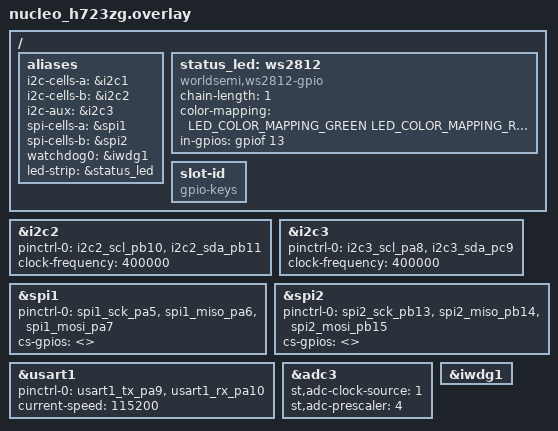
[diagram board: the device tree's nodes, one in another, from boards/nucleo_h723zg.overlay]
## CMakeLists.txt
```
cmake_minimum_required(VERSION 3.20.0)
find_package(Zephyr REQUIRED HINTS $ENV{ZEPHYR_BASE})
project(cellsim-card)

target_sources(app PRIVATE
    src/main.c
    src/card_id.c
    src/cell.c
    src/self_test.c
    src/watchdog.c
    src/health.c
    src/network.c
    src/led.c
)
```

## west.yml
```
manifest:
  remotes:
    - name: zephyrproject-rtos
      url-base: https://github.com/zephyrproject-rtos

  projects:
    - name: zephyr
      remote: zephyrproject-rtos
      revision: v4.0.0
      import:
        name-allowlist:
          - cmsis
          - hal_stm32
          - mbedtls
          - mcuboot
          - net-tools

  self:
    path: card
```

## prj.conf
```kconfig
# CellSim Card Firmware - Zephyr Configuration
# Target: STM32H723 + LAN8742A (Zephyr 4.0.0)

# --- Core ---
CONFIG_MAIN_STACK_SIZE=4096
CONFIG_HEAP_MEM_POOL_SIZE=16384
CONFIG_SYSTEM_WORKQUEUE_STACK_SIZE=2048

# --- Networking ---
CONFIG_NETWORKING=y
CONFIG_NET_IPV4=y
CONFIG_NET_TCP=y
CONFIG_NET_UDP=y
CONFIG_NET_SOCKETS=y

# Network buffers (required for TCP/UDP)
CONFIG_NET_PKT_RX_COUNT=16
CONFIG_NET_PKT_TX_COUNT=16
CONFIG_NET_BUF_RX_COUNT=32
CONFIG_NET_BUF_TX_COUNT=32
CONFIG_NET_MAX_CONTEXTS=8

# DHCP client (fallback to static if no DHCP)
CONFIG_NET_DHCPV4=y

# DNS / mDNS for card discovery
CONFIG_DNS_RESOLVER=y
CONFIG_MDNS_RESPONDER=y
CONFIG_DNS_SD=y
CONFIG_MDNS_RESOLVER=y
CONFIG_NET_HOSTNAME_ENABLE=y
CONFIG_NET_HOSTNAME_MAX_LEN=32
CONFIG_ZVFS_POLL_MAX=8

# --- Ethernet ---
CONFIG_NET_L2_ETHERNET=y
CONFIG_ETH_STM32_HAL=y

# --- I2C ---
CONFIG_I2C=y

# --- SPI (cell ADCs: ADS131M04 via ISO7741 isolators) ---
CONFIG_SPI=y

# --- GPIO ---
CONFIG_GPIO=y

# --- ADC (internal, for input voltage + temperature) ---
CONFIG_ADC=y

# --- Sensor (needed for STM32 internal temp sensor driver) ---
CONFIG_SENSOR=y

# --- MCUboot (OTA firmware update) ---
# Disabled for initial build — requires MCUboot partition table + signing key.
# Re-enable once bootloader integration is done.
# CONFIG_BOOTLOADER_MCUBOOT=y

# --- MCUmgr (SMP over UDP for firmware push from CM5) ---
# Disabled until MCUboot is enabled.
# CONFIG_MCUMGR=y
# CONFIG_MCUMGR_TRANSPORT_UDP=y
# CONFIG_MCUMGR_GRP_IMG=y
# CONFIG_MCUMGR_GRP_OS=y

# --- UART (backplane slot mux for remote flash/debug) ---
CONFIG_SERIAL=y

# --- Watchdog (hardware IWDG for firmware hang recovery) ---
CONFIG_WATCHDOG=y

# --- Internal temperature sensor ---
# Disabled: requires die_temp DT node which nucleo_h723zg base DTS doesn't define.
# Re-enable once custom board DTS is created with proper die_temp node.
# CONFIG_STM32_TEMP=y

# --- Shell (debug console over UART) ---
CONFIG_SHELL=y
CONFIG_SHELL_BACKEND_SERIAL=y

# --- Logging ---
CONFIG_LOG=y
CONFIG_LOG_DEFAULT_LEVEL=3

# --- Status LED (SK6805-EC20, WS2812-compatible via GPIO bit-bang) ---
CONFIG_LED_STRIP=y
CONFIG_WS2812_STRIP=y
CONFIG_WS2812_STRIP_GPIO=y

# --- Reboot support (for CMD_REBOOT) ---
CONFIG_REBOOT=y

# --- Float support (needed for health monitoring printfs) ---
CONFIG_FPU=y
CONFIG_CBPRINTF_FP_SUPPORT=y
```

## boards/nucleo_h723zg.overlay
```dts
/*
 * CellSim Card - Zephyr Device Tree Overlay
 *
 * Based on nucleo_h723zg, customized for the CellSim card PCB.
 *
 * I2C Bus Architecture (control path — DACs, GPIO, temp):
 *   i2c1 -> TCA9548A #1 -> cells 0-3 (each behind ISO1640)
 *   i2c2 -> TCA9548A #2 -> cells 4-7 (each behind ISO1640)
 *   i2c3 -> 24AA025E48 EEPROM (card identity) + board temp sensor
 *
 * SPI Bus Architecture (measurement path — ADC):
 *   spi1 -> ISO7741 ×4 -> cells 0-3 ADS131M04 (MISO via CD74HC4052)
 *   spi2 -> ISO7741 ×4 -> cells 4-7 ADS131M04 (MISO via CD74HC4052)
 *
 * UART:
 *   usart1 -> backplane slot mux -> CM5 (remote debug/flash)
 *   usart3 -> ST-LINK virtual COM (debug console, default on base board)
 *
 * ADC:
 *   adc3 -> internal temp (ch18), Vrefint (ch19), input voltage divider
 *
 * Ethernet:
 *   RMII -> LAN8742A -> backplane (configured in base board DTS)
 *
 * TODO: Finalize pin assignments once PCB layout is done.
 *       These are reasonable defaults for the nucleo_h723zg.
 */

#include <st/h7/stm32h723zgtx-pinctrl.dtsi>
#include <dt-bindings/led/led.h>

/ {
    aliases {
        /* I2C buses for cell blocks (control path) */
        i2c-cells-a = &i2c1;
        i2c-cells-b = &i2c2;
        i2c-aux = &i2c3;

        /* SPI buses for cell ADCs (measurement path) */
        spi-cells-a = &spi1;
        spi-cells-b = &spi2;

        /* Hardware watchdog */
        watchdog0 = &iwdg1;

        /* Status LED (SK6805-EC20, WS2812-compatible) */
        led-strip = &status_led;
    };

    /* SK6805-EC20 addressable RGB status LED on PF13 */
    status_led: ws2812 {
        compatible = "worldsemi,ws2812-gpio";
        chain-length = <1>;
        color-mapping = <LED_COLOR_MAPPING_GREEN
                         LED_COLOR_MAPPING_RED
                         LED_COLOR_MAPPING_BLUE>;
        in-gpios = <&gpiof 13 0>;
    };

    /* Slot ID GPIO inputs (active-low, coded by backplane resistors) */
    slot-id {
        compatible = "gpio-keys";
        /* TODO: assign actual GPIO pins once schematic is finalized
         * 4 bits for 16 slots (reduced from 5 bits / 20 slots)
         *
         * Example (placeholder pins):
         * slot-id-0 { gpios = <&gpiod 0 (GPIO_PULL_UP | GPIO_ACTIVE_LOW)>; };
         * slot-id-1 { gpios = <&gpiod 1 (GPIO_PULL_UP | GPIO_ACTIVE_LOW)>; };
         * slot-id-2 { gpios = <&gpiod 2 (GPIO_PULL_UP | GPIO_ACTIVE_LOW)>; };
         * slot-id-3 { gpios = <&gpiod 3 (GPIO_PULL_UP | GPIO_ACTIVE_LOW)>; };
         */
    };

    /*
     * SPI ADC chip-select and MISO mux GPIO pins.
     * Each SPI bus has:
     *   4× CS lines (one per cell's ADS131M04, directly to ISO7741)
     *   2× MISO mux select (CD74HC4052 address bits A0/A1)
     *
     * TODO: assign actual GPIO pins once schematic is finalized.
     *
     * spi1-adc-gpios {
     *     compatible = "gpio-leds";
     *     spi1_cs0 { gpios = <&gpioe 0 GPIO_ACTIVE_LOW>; };
     *     spi1_cs1 { gpios = <&gpioe 1 GPIO_ACTIVE_LOW>; };
     *     spi1_cs2 { gpios = <&gpioe 2 GPIO_ACTIVE_LOW>; };
     *     spi1_cs3 { gpios = <&gpioe 3 GPIO_ACTIVE_LOW>; };
     *     spi1_mux_a0 { gpios = <&gpioe 4 GPIO_ACTIVE_HIGH>; };
     *     spi1_mux_a1 { gpios = <&gpioe 5 GPIO_ACTIVE_HIGH>; };
     * };
     *
     * spi2-adc-gpios {
     *     compatible = "gpio-leds";
     *     spi2_cs0 { gpios = <&gpioe 6 GPIO_ACTIVE_LOW>; };
     *     spi2_cs1 { gpios = <&gpioe 7 GPIO_ACTIVE_LOW>; };
     *     spi2_cs2 { gpios = <&gpioe 8 GPIO_ACTIVE_LOW>; };
     *     spi2_cs3 { gpios = <&gpioe 9 GPIO_ACTIVE_LOW>; };
     *     spi2_mux_a0 { gpios = <&gpioe 10 GPIO_ACTIVE_HIGH>; };
     *     spi2_mux_a1 { gpios = <&gpioe 11 GPIO_ACTIVE_HIGH>; };
     * };
     */
};

/* I2C1: Cells 0-3 (via TCA9548A #1) — pinctrl from base board (PB8/PB9) */
/* Already configured in base board DTS, just override clock if needed */

/* I2C2: Cells 4-7 (via TCA9548A #2) — PB10 (SCL), PB11 (SDA) */
&i2c2 {
    pinctrl-0 = <&i2c2_scl_pb10 &i2c2_sda_pb11>;
    pinctrl-names = "default";
    status = "okay";
    clock-frequency = <400000>;
};

/* I2C3: Card identity EEPROM (24AA025E48) + board temp sensor — PA8 (SCL), PC9 (SDA) */
&i2c3 {
    pinctrl-0 = <&i2c3_scl_pa8 &i2c3_sda_pc9>;
    pinctrl-names = "default";
    status = "okay";
    clock-frequency = <400000>;
};

/* SPI1: Cells 0-3 ADC (ADS131M04 via ISO7741) — PA5 (SCK), PA7 (MOSI), PA6 (MISO) */
&spi1 {
    pinctrl-0 = <&spi1_sck_pa5 &spi1_miso_pa6 &spi1_mosi_pa7>;
    pinctrl-names = "default";
    status = "okay";
    /* CS managed by software GPIO (per-cell through ISO7741) */
    cs-gpios = <>;
};

/* SPI2: Cells 4-7 ADC (ADS131M04 via ISO7741) — PB13 (SCK), PB15 (MOSI), PB14 (MISO) */
&spi2 {
    pinctrl-0 = <&spi2_sck_pb13 &spi2_miso_pb14 &spi2_mosi_pb15>;
    pinctrl-names = "default";
    status = "okay";
    cs-gpios = <>;
};

/* USART1: Backplane slot mux (remote debug/flash from CM5) — PA9 (TX), PA10 (RX) */
&usart1 {
    pinctrl-0 = <&usart1_tx_pa9 &usart1_rx_pa10>;
    pinctrl-names = "default";
    status = "okay";
    current-speed = <115200>;
};

/* ADC3: Internal sensors + input voltage divider */
&adc3 {
    status = "okay";
    st,adc-clock-source = <1>;  /* SYNC clock (AHB bus clock / prescaler) */
    st,adc-prescaler = <4>;     /* AHB clock prescaler */
    /* Internal channels (temp sensor ch18, Vrefint ch19) are always available.
     * External channel for input voltage divider: TODO assign pin/channel.
     */
};

/* Independent Watchdog (IWDG) */
&iwdg1 {
    status = "okay";
};

/* Ethernet: RMII to LAN8742A PHY — pinctrl from base board DTS */
/* &mac and &mdio already configured in base board DTS */
```

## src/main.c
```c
/*
 * CellSim Card Firmware
 * =====================
 * Zephyr RTOS application for the CellSim v2 cell card.
 *
 * Architecture:
 *   - 100 Hz control loop: reads ADCs, updates DACs, runs calibration
 *   - UDP streaming: sends measurement packets to CM5 at 100 Hz
 *   - TCP command server: receives commands from CM5
 *   - mDNS: advertises as cellsim-card-{slot_id}.local
 *   - MCUmgr/SMP: OTA firmware update over UDP
 *   - Self-test: BIST on all 8 cells at boot + on demand
 *   - Watchdog: hardware IWDG + CM5 heartbeat monitor
 *   - Health: internal temp, Vrefint, input voltage in every packet
 *
 * I2C topology (per card):
 *   I2C1 -> TCA9548A -> [ISO1640 -> cell devices] x 4  (cells 0-3)
 *   I2C2 -> TCA9548A -> [ISO1640 -> cell devices] x 4  (cells 4-7)
 *
 * Per-cell devices (on isolated side):
 *   - MCP4725 DAC ×2 (buck + LDO setpoints, via I2C)
 *   - ADS131M04 ADC (4ch simultaneous, via SPI + ISO7741 isolator)
 *   - TCA6408 GPIO expander (relay, enable, load switch, 2/4-wire, via I2C)
 *   - TMP117 temperature sensor (via I2C)
 *
 * Backplane signals:
 *   - USART1 (PA9 TX, PA10 RX): remote debug/flash via CM5 slot mux
 *   - BOOT0: ROM bootloader entry (pulled low on card, driven by CM5 mux)
 *   - NRST: reset (pulled high on card, driven by CM5 mux)
 *   - Slot ID: 4 GPIO inputs (active-low, coded by backplane resistors)
 *   - Input voltage: ADC3 via 100k/10k divider from 24V bus
 */

#include <zephyr/kernel.h>
#include <zephyr/drivers/gpio.h>
#include <zephyr/logging/log.h>

#include "card_id.h"
#include "cell.h"
#include "led.h"
#include "self_test.h"
#include "watchdog.h"
#include "health.h"
#include "network.h"

LOG_MODULE_REGISTER(cellsim, LOG_LEVEL_INF);

/* Firmware version (embedded in mDNS TXT record and self-test response) */
#define FW_VERSION_MAJOR 2
#define FW_VERSION_MINOR 0
#define FW_VERSION_PATCH 0

/**
 * Read slot ID from 4 GPIO pins (active-low, coded by backplane resistors).
 * Returns 0-15 for valid slots.
 */
static uint8_t read_slot_id(void)
{
    /* TODO: read 4 GPIO pins and decode slot ID
     * Slot ID pins are active-low: 0 = pull-down on backplane, 1 = pull-up
     * Binary encoding: slot_id = ~(GPIO3:GPIO0) & 0x0F
     */
    return 0; /* Placeholder: slot 0 */
}

int main(void)
{
    LOG_INF("CellSim card firmware v%d.%d.%d starting...",
            FW_VERSION_MAJOR, FW_VERSION_MINOR, FW_VERSION_PATCH);

    /* Read slot ID from backplane resistor coding */
    uint8_t slot_id = read_slot_id();
    LOG_INF("Slot ID: %d", slot_id);

    /* Read card identity EEPROM (24AA025E48 on I2C3) */
    int ret = card_id_init();
    if (ret != 0) {
        LOG_WRN("Card identity EEPROM read failed: %d (using fallback ID)", ret);
    }

    /* Initialize status LED and set booting color (blue) */
    ret = led_init();
    if (ret != 0) {
        LOG_WRN("Status LED init failed: %d (continuing without LED)", ret);
    } else {
        led_set_status_booting();
    }

    /* Initialize health monitoring (ADC3: internal temp, Vrefint, input voltage) */
    ret = health_init();
    if (ret != 0) {
        LOG_WRN("Health monitoring init failed: %d (continuing)", ret);
    }

    /* Initialize watchdog (hardware IWDG + CM5 heartbeat monitor) */
    ret = watchdog_init();
    if (ret != 0) {
        LOG_ERR("Watchdog init failed: %d", ret);
        /* Continue anyway — watchdog is important but not fatal */
    }

    /* Run self-test on all 8 cells */
    struct self_test_result st_result;
    ret = self_test_run(&st_result);
    if (ret != 0) {
        LOG_ERR("Self-test failed to run: %d", ret);
    } else if (!st_result.all_passed) {
        LOG_WRN("Self-test: some cells FAILED (MCU: %.1f°C, Vin: %.1fV)",
                (double)st_result.mcu_temp_celsius,
                (double)st_result.input_voltage);
        led_set_status_warning();
    } else {
        LOG_INF("Self-test: ALL PASSED (MCU: %.1f°C, Vin: %.1fV)",
                (double)st_result.mcu_temp_celsius,
                (double)st_result.input_voltage);
        led_set_status_ok();
    }

    /* Initialize cell control HAL (DACs, ADCs, GPIO expanders) */
    ret = cell_init();
    if (ret != 0) {
        LOG_ERR("Cell HAL init failed: %d", ret);
        /* Non-fatal: some cells may still work */
    }

    /* Initialize network services (mDNS, TCP, UDP) */
    ret = network_init(slot_id);
    if (ret != 0) {
        LOG_ERR("Network init failed: %d", ret);
        return ret;
    }

    /* Start TCP command server thread */
    ret = network_start_cmd_server();
    if (ret != 0) {
        LOG_ERR("Failed to start command server: %d", ret);
    }

    /* Start UDP measurement streaming + 100 Hz control loop */
    ret = network_start_meas_stream();
    if (ret != 0) {
        LOG_ERR("Failed to start measurement stream: %d", ret);
    }

    LOG_INF("CellSim card firmware initialized (slot %d)", slot_id);

    /* Main thread: nothing more to do, work happens in spawned threads.
     * Zephyr idle thread handles power management. */
    return 0;
}
```

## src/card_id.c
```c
/*
 * CellSim Card — Card Identity (24AA025E48 EEPROM) Implementation
 */

#include "card_id.h"

#include <zephyr/kernel.h>
#include <zephyr/device.h>
#include <zephyr/drivers/i2c.h>
#include <zephyr/logging/log.h>
#include <stdio.h>

LOG_MODULE_REGISTER(card_id, LOG_LEVEL_INF);

/* 24AA025E48 on I2C3 */
#define EEPROM_ADDR         0x50
#define EEPROM_EUI48_OFFSET 0xFA  /* EUI-48 starts at byte address 0xFA */

static uint8_t eui48[CARD_ID_EUI48_LEN];
static bool id_valid;

int card_id_init(void)
{
    const struct device *bus = DEVICE_DT_GET(DT_ALIAS(i2c_aux));
    if (!device_is_ready(bus)) {
        LOG_ERR("I2C3 (card identity bus) not ready");
        return -ENODEV;
    }

    /* Read 6 bytes starting at address 0xFA */
    uint8_t reg = EEPROM_EUI48_OFFSET;
    int ret = i2c_write_read(bus, EEPROM_ADDR, &reg, 1,
                             eui48, CARD_ID_EUI48_LEN);
    if (ret != 0) {
        LOG_ERR("24AA025E48 EEPROM read failed: %d", ret);
        id_valid = false;
        return ret;
    }

    /* Sanity: check it's not all-FF (blank EEPROM) or all-00 */
    bool all_ff = true, all_00 = true;
    for (int i = 0; i < CARD_ID_EUI48_LEN; i++) {
        if (eui48[i] != 0xFF) all_ff = false;
        if (eui48[i] != 0x00) all_00 = false;
    }

    if (all_ff || all_00) {
        LOG_WRN("EEPROM EUI-48 appears blank (all %s)",
                all_ff ? "0xFF" : "0x00");
        id_valid = false;
        return -ENODATA;
    }

    id_valid = true;

    char id_str[18];
    card_id_format_eui48(id_str, sizeof(id_str));
    LOG_INF("Card ID: %s", id_str);

    return 0;
}

bool card_id_get_eui48(uint8_t out[CARD_ID_EUI48_LEN])
{
    if (!id_valid || out == NULL) {
        return false;
    }
    memcpy(out, eui48, CARD_ID_EUI48_LEN);
    return true;
}

int card_id_format_eui48(char *buf, size_t buf_len)
{
    if (buf == NULL || buf_len < 18) {
        return 0;
    }
    return snprintf(buf, buf_len, "%02X:%02X:%02X:%02X:%02X:%02X",
                    eui48[0], eui48[1], eui48[2],
                    eui48[3], eui48[4], eui48[5]);
}
```

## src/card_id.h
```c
/*
 * CellSim Card — Card Identity (24AA025E48 EEPROM)
 *
 * Reads the factory-programmed EUI-48 from the Microchip 24AA025E48
 * EEPROM on I2C3. Used as:
 *   - Unique card identifier (survives MCU replacement)
 *   - Ethernet MAC address for LAN8742A
 *   - Calibration data binding key
 *
 * The EUI-48 is stored at EEPROM addresses 0xFA–0xFF (read-only).
 * The first 250 bytes (0x00–0xF9) are user-writable EEPROM.
 */

#ifndef CELLSIM_CARD_ID_H
#define CELLSIM_CARD_ID_H

#include <stdbool.h>
#include <stdint.h>

#define CARD_ID_EUI48_LEN  6

/**
 * Initialize card identity by reading EUI-48 from EEPROM on I2C3.
 *
 * @return 0 on success, negative errno on error
 */
int card_id_init(void);

/**
 * Get the 6-byte EUI-48 (MAC address).
 *
 * @param out  Buffer of at least CARD_ID_EUI48_LEN bytes
 * @return true if ID is valid (init succeeded), false otherwise
 */
bool card_id_get_eui48(uint8_t out[CARD_ID_EUI48_LEN]);

/**
 * Format EUI-48 as "XX:XX:XX:XX:XX:XX" string.
 *
 * @param buf      Output buffer (at least 18 bytes)
 * @param buf_len  Size of output buffer
 * @return Number of characters written (excluding null terminator)
 */
int card_id_format_eui48(char *buf, size_t buf_len);

#endif /* CELLSIM_CARD_ID_H */
```

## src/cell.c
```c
/*
 * CellSim Card — Cell Control HAL Implementation
 *
 * Controls per-cell voltage/current through:
 *   I2C path: MCP4725 DACs (buck + LDO setpoints), TCA6408 GPIO, TMP117 temp
 *   SPI path: ADS131M04 24-bit ADC (4 simultaneous channels)
 *
 * Bus architecture:
 *   I2C1 → TCA9548A → Cells 0–3  |  SPI1 → ISO7741 ×4 → Cells 0–3 ADC
 *   I2C2 → TCA9548A → Cells 4–7  |  SPI2 → ISO7741 ×4 → Cells 4–7 ADC
 */

#include "cell.h"
#include "self_test.h"

#include <zephyr/kernel.h>
#include <zephyr/device.h>
#include <zephyr/drivers/i2c.h>
#include <zephyr/drivers/spi.h>
#include <zephyr/drivers/gpio.h>
#include <zephyr/logging/log.h>
#include <string.h>

LOG_MODULE_REGISTER(cell, LOG_LEVEL_INF);

/* ── I2C addresses (isolated side, behind TCA9548A) ───────────── */
#define TCA9548A_ADDR       0x70
#define MCP4725_BUCK_ADDR   0x61  /* A0=VIN (spec §4.2.2) */
#define MCP4725_LDO_ADDR    0x60  /* A0=GND (spec §4.2.3) */
#define TCA6408_ADDR        0x20
#define TMP117_ADDR         0x49  /* ADDR=VDD */

/* ── TCA6408 registers ────────────────────────────────────────── */
#define TCA6408_OUTPUT      0x01
#define TCA6408_CONFIG      0x03  /* 0 = output, 1 = input */

/* ── ADS131M04 SPI protocol ───────────────────────────────────── */
/*
 * Frame format (24-bit word size, default):
 *   TX: [CMD] [REG_DATA/0] [0] [0] [0] [CRC/0]
 *   RX: [STATUS]  [CH0]  [CH1]  [CH2]  [CH3]  [CRC]
 *
 * 6 words × 3 bytes = 18 bytes per frame.
 */
#define ADS131_FRAME_WORDS  6
#define ADS131_WORD_BYTES   3
#define ADS131_FRAME_BYTES  (ADS131_FRAME_WORDS * ADS131_WORD_BYTES)

/* Commands (upper byte of 16-bit command, zero-padded to 24 bits) */
#define ADS131_CMD_NULL     0x0000
#define ADS131_CMD_RESET    0x0011
#define ADS131_CMD_STANDBY  0x0022
#define ADS131_CMD_WAKEUP   0x0033
#define ADS131_CMD_RREG(a)  (0xA000 | (((a) & 0x3F) << 7))
#define ADS131_CMD_WREG(a)  (0x6000 | (((a) & 0x3F) << 7))

/* Registers */
#define ADS131_REG_ID       0x00
#define ADS131_REG_STATUS   0x01
#define ADS131_REG_MODE     0x02
#define ADS131_REG_CLOCK    0x03
#define ADS131_REG_CFG      0x06

/* MODE register bits */
#define ADS131_MODE_CRC_DIS 0x000000  /* CRC disabled (bits 5:4 = 00) */

/* CLOCK register: enable all 4 channels, OSR = 4096 (4 kSPS) */
#define ADS131_CLOCK_DEFAULT  0x0F0E
/*   bits [3:0] = 0xF: CH0-CH3 enabled
 *   bits [4]   = 0:   internal osc
 *   bits [7:5] = 0:   no divide
 *   bits [11:8] = 0xF: OSR = 4096 → ~4 kSPS
 *   (firmware reads at 100–1000 Hz, well below conversion rate)
 */

/* ── MCP4725 DAC ──────────────────────────────────────────────── */
#define DAC_MAX_CODE        4095
#define DAC_MAX_OUTPUT_MV   5000

/* ── Buck converter parameters ────────────────────────────────── */
#define BUCK_MAX_MV         5500  /* Max buck output (spec §4.2.2) */
#define LDO_HEADROOM_MV     500   /* Buck tracks LDO output + headroom (spec §4.2.3) */

/* ── TMP117 ───────────────────────────────────────────────────── */
#define TMP117_REG_TEMP     0x00

/* ── SPI ADC GPIO assignments ─────────────────────────────────── */
/*
 * TODO: Finalize pin assignments when PCB layout is done.
 * These placeholders match the overlay comments (GPIOE pins).
 *
 * SPI1 (cells 0-3): CS on PE0-PE3, mux on PE4/PE5
 * SPI2 (cells 4-7): CS on PE6-PE9, mux on PE10/PE11
 */
static const gpio_pin_t adc_cs_pins[CELL_COUNT] = {
    0, 1, 2, 3,    /* SPI1: cells 0-3 on GPIOE */
    6, 7, 8, 9,    /* SPI2: cells 4-7 on GPIOE */
};

static const gpio_pin_t mux_a0_pins[2] = { 4, 10 };  /* per SPI bus */
static const gpio_pin_t mux_a1_pins[2] = { 5, 11 };

/* ── Bus state ────────────────────────────────────────────────── */

/* I2C buses (cells 0-3 and 4-7 control path) */
static const struct device *i2c_bus[CELLSIM_NUM_I2C_BUSES];
static struct k_mutex i2c_lock[CELLSIM_NUM_I2C_BUSES];

/* SPI buses (cells 0-3 and 4-7 measurement path) */
static const struct device *spi_bus[2];
static struct spi_config spi_cfg[2];
static struct k_mutex spi_lock[2];

/* GPIO port for ADC CS and mux select (all on GPIOE — TODO: update if changed) */
static const struct device *adc_gpio_port;

/* Per-cell state */
static struct cell_state cells[CELL_COUNT];

/* Per-cell TCA6408 output register shadow */
static uint8_t gpio_shadow[CELL_COUNT];

/* ── Helpers ──────────────────────────────────────────────────── */

static inline int i2c_idx(uint8_t cell_id)   { return cell_id / CELLS_PER_BUS; }
static inline int spi_idx(uint8_t cell_id)   { return cell_id / CELLS_PER_BUS; }
static inline int mux_channel(uint8_t cell_id) { return cell_id % CELLS_PER_BUS; }

static const struct device *cell_i2c(uint8_t cell_id)
{
    return i2c_bus[i2c_idx(cell_id)];
}

/* ── TCA9548A I2C Mux ────────────────────────────────────────── */

static int tca9548a_select(const struct device *bus, uint8_t channel)
{
    uint8_t mask = (channel < 8) ? (1 << channel) : 0x00;
    return i2c_write(bus, &mask, 1, TCA9548A_ADDR);
}

static int i2c_mux_select(uint8_t cell_id)
{
    return tca9548a_select(cell_i2c(cell_id), mux_channel(cell_id));
}

static int i2c_mux_deselect(uint8_t cell_id)
{
    return tca9548a_select(cell_i2c(cell_id), 0xFF);
}

/* ── MCP4725 DAC ──────────────────────────────────────────────── */

static int mcp4725_write(const struct device *bus, uint8_t addr, uint16_t code)
{
    if (code > DAC_MAX_CODE) {
        code = DAC_MAX_CODE;
    }
    /* Fast write: [0 C1 C0 PD1 PD0 D11..D8] [D7..D0] */
    uint8_t buf[2] = {
        (uint8_t)(code >> 8) & 0x0F,
        (uint8_t)(code & 0xFF),
    };
    return i2c_write(bus, buf, 2, addr);
}

static uint16_t mv_to_dac(uint16_t mv)
{
    if (mv > DAC_MAX_OUTPUT_MV) {
        mv = DAC_MAX_OUTPUT_MV;
    }
    return (uint16_t)(((uint32_t)mv * DAC_MAX_CODE) / DAC_MAX_OUTPUT_MV);
}

/* ── TCA6408 GPIO Expander ────────────────────────────────────── */

static int tca6408_write_output(const struct device *bus, uint8_t value)
{
    uint8_t buf[2] = { TCA6408_OUTPUT, value };
    return i2c_write(bus, buf, sizeof(buf), TCA6408_ADDR);
}

static int tca6408_init_cell(const struct device *bus)
{
    /* All controllable bits as outputs (0 = output) */
    uint8_t output_mask = GPIO_DMM_CAL | GPIO_BUCK_EN | GPIO_LDO_EN |
                          GPIO_LOAD_SWITCH | GPIO_OUTPUT_RELAY |
                          GPIO_EXT_LOAD_SW | GPIO_FOUR_WIRE;
    uint8_t config = (uint8_t)~output_mask;
    uint8_t buf[2] = { TCA6408_CONFIG, config };
    int ret = i2c_write(bus, buf, sizeof(buf), TCA6408_ADDR);
    if (ret != 0) {
        return ret;
    }
    return tca6408_write_output(bus, 0x00);
}

/* ── TMP117 Temperature Sensor ────────────────────────────────── */

static int tmp117_read(const struct device *bus, int16_t *temp_c10)
{
    uint8_t reg = TMP117_REG_TEMP;
    uint8_t data[2];
    int ret = i2c_write_read(bus, TMP117_ADDR, &reg, 1, data, 2);
    if (ret != 0) {
        return ret;
    }
    /* TMP117: 7.8125 m°C/LSB → °C×10: raw * 78125 / 1000000 */
    int16_t raw = (int16_t)((data[0] << 8) | data[1]);
    *temp_c10 = (int16_t)((int32_t)raw * 78125 / 1000000);
    return 0;
}

/* ── ADS131M04 SPI ADC ────────────────────────────────────────── */

/* Pack a 24-bit word into 3 bytes (MSB first) */
static void ads131_pack_word(uint8_t *buf, uint32_t word)
{
    buf[0] = (uint8_t)(word >> 16);
    buf[1] = (uint8_t)(word >> 8);
    buf[2] = (uint8_t)(word);
}

/* Unpack 3 bytes (MSB first) into a 24-bit value, sign-extended to int32 */
static int32_t ads131_unpack_word(const uint8_t *buf)
{
    int32_t val = ((int32_t)buf[0] << 16) | (buf[1] << 8) | buf[2];
    /* Sign-extend from 24-bit */
    if (val & 0x800000) {
        val |= (int32_t)0xFF000000;
    }
    return val;
}

/* Assert/deassert CS for a specific cell */
static void adc_cs_assert(uint8_t cell_id)
{
    gpio_pin_set(adc_gpio_port, adc_cs_pins[cell_id], 0);  /* Active low */
}

static void adc_cs_deassert(uint8_t cell_id)
{
    gpio_pin_set(adc_gpio_port, adc_cs_pins[cell_id], 1);
}

/* Set MISO mux to select a cell's return channel */
static void adc_mux_select(uint8_t cell_id)
{
    int bidx = spi_idx(cell_id);
    int ch = mux_channel(cell_id);  /* 0-3 → 2-bit address */
    gpio_pin_set(adc_gpio_port, mux_a0_pins[bidx], ch & 0x01);
    gpio_pin_set(adc_gpio_port, mux_a1_pins[bidx], (ch >> 1) & 0x01);
}

/*
 * Perform one ADS131M04 SPI frame exchange.
 *   cmd:     16-bit command (zero-padded to 24 bits in frame)
 *   reg_data: optional register data word (for WREG commands, else 0)
 *   status:  output: response status word (may be NULL)
 *   ch_data: output: 4-channel data array (may be NULL)
 *
 * Returns 0 on success, negative errno on SPI error.
 */
static int ads131_transfer(uint8_t cell_id, uint16_t cmd, uint32_t reg_data,
                           uint32_t *status, int32_t ch_data[4])
{
    int bidx = spi_idx(cell_id);
    uint8_t tx[ADS131_FRAME_BYTES] = {0};
    uint8_t rx[ADS131_FRAME_BYTES] = {0};

    /* Build TX frame */
    ads131_pack_word(&tx[0], (uint32_t)cmd << 8);  /* CMD in word 0 */
    if (reg_data != 0) {
        ads131_pack_word(&tx[3], reg_data);  /* REG data in word 1 */
    }
    /* Words 2-5 are zero (padding + CRC placeholder) */

    struct spi_buf tx_buf = { .buf = tx, .len = ADS131_FRAME_BYTES };
    struct spi_buf rx_buf = { .buf = rx, .len = ADS131_FRAME_BYTES };
    struct spi_buf_set tx_set = { .buffers = &tx_buf, .count = 1 };
    struct spi_buf_set rx_set = { .buffers = &rx_buf, .count = 1 };

    /* Set MISO mux, assert CS */
    adc_mux_select(cell_id);
    adc_cs_assert(cell_id);

    int ret = spi_transceive(spi_bus[bidx], &spi_cfg[bidx], &tx_set, &rx_set);

    adc_cs_deassert(cell_id);

    if (ret != 0) {
        return ret;
    }

    /* Parse RX frame */
    if (status != NULL) {
        *status = ((uint32_t)rx[0] << 16) | (rx[1] << 8) | rx[2];
    }
    if (ch_data != NULL) {
        for (int i = 0; i < 4; i++) {
            ch_data[i] = ads131_unpack_word(&rx[3 + i * ADS131_WORD_BYTES]);
        }
    }

    return 0;
}

/* Write an ADS131M04 register (takes effect on next frame) */
static int ads131_write_reg(uint8_t cell_id, uint8_t reg, uint32_t data)
{
    return ads131_transfer(cell_id, ADS131_CMD_WREG(reg), data, NULL, NULL);
}

/* Initialize one ADS131M04 (reset + configure) */
static int ads131_init_cell(uint8_t cell_id)
{
    int ret;

    /* Software reset */
    ret = ads131_transfer(cell_id, ADS131_CMD_RESET, 0, NULL, NULL);
    if (ret != 0) {
        return ret;
    }
    k_sleep(K_MSEC(5));  /* Wait for reset (tPOR) */

    /* Disable CRC for simpler framing */
    ret = ads131_write_reg(cell_id, ADS131_REG_MODE, ADS131_MODE_CRC_DIS);
    if (ret != 0) {
        return ret;
    }

    /* Send NULL to clock in the WREG response */
    ret = ads131_transfer(cell_id, ADS131_CMD_NULL, 0, NULL, NULL);
    if (ret != 0) {
        return ret;
    }

    /* Configure CLOCK: all 4 channels enabled, OSR=4096 (~4 kSPS) */
    ret = ads131_write_reg(cell_id, ADS131_REG_CLOCK, ADS131_CLOCK_DEFAULT);
    if (ret != 0) {
        return ret;
    }

    /* Clock in the WREG response */
    return ads131_transfer(cell_id, ADS131_CMD_NULL, 0, NULL, NULL);
}

/* Read all 4 channels from one ADS131M04. Returns raw 24-bit signed values. */
static int ads131_read_channels(uint8_t cell_id, int32_t ch_data[4])
{
    return ads131_transfer(cell_id, ADS131_CMD_NULL, 0, NULL, ch_data);
}

/* ── ADC Scaling ──────────────────────────────────────────────── */

/*
 * Convert 24-bit signed ADC raw to millivolts at the signal source,
 * applying the voltage divider ratio.
 *
 * V_adc = raw × Vref / 2^23
 * V_signal = V_adc × divider_ratio
 */
static uint16_t adc_raw_to_signal_mv(int32_t raw, float divider)
{
    if (raw < 0) {
        return 0;
    }
    float v_adc_mv = (float)raw * (float)ADC_VREF_MV / (float)ADC_FULL_SCALE;
    float v_signal = v_adc_mv * divider;
    if (v_signal > 65535.0f) {
        return 65535;
    }
    return (uint16_t)v_signal;
}

/*
 * Convert current-sense ADC raw to microamps.
 *
 * V_adc = raw × Vref / 2^23
 * V_ina = V_adc × ADC_VDIV_CURRENT    (undo 2:5 divider)
 * I = V_ina / (R_shunt × Gain)
 */
static uint32_t adc_raw_to_current_ua(int32_t raw)
{
    if (raw < 0) {
        return 0;
    }
    float v_adc_mv = (float)raw * (float)ADC_VREF_MV / (float)ADC_FULL_SCALE;
    float v_ina_mv = v_adc_mv * ADC_VDIV_CURRENT;
    float i_ma = v_ina_mv / (ADC_IOUT_SHUNT_R * ADC_IOUT_INA_GAIN * 1000.0f);
    return (uint32_t)(i_ma * 1000.0f);  /* mA → µA */
}

/* ── SPI GPIO Init ────────────────────────────────────────────── */

static int adc_gpio_init(void)
{
    adc_gpio_port = DEVICE_DT_GET(DT_NODELABEL(gpioe));
    if (!device_is_ready(adc_gpio_port)) {
        LOG_ERR("ADC GPIO port (GPIOE) not ready");
        return -ENODEV;
    }

    /* Configure CS pins (active low, default high = deasserted) */
    for (int i = 0; i < CELL_COUNT; i++) {
        int ret = gpio_pin_configure(adc_gpio_port, adc_cs_pins[i],
                                     GPIO_OUTPUT_HIGH);
        if (ret != 0) {
            LOG_ERR("Cell %d: CS GPIO config failed: %d", i, ret);
            return ret;
        }
    }

    /* Configure MISO mux select pins (output, default 0) */
    for (int b = 0; b < 2; b++) {
        gpio_pin_configure(adc_gpio_port, mux_a0_pins[b], GPIO_OUTPUT_LOW);
        gpio_pin_configure(adc_gpio_port, mux_a1_pins[b], GPIO_OUTPUT_LOW);
    }

    return 0;
}

/* ── Public API ───────────────────────────────────────────────── */

int cell_init(void)
{
    int ret;

    /* I2C bus init */
    i2c_bus[0] = DEVICE_DT_GET(DT_ALIAS(i2c_cells_a));
    i2c_bus[1] = DEVICE_DT_GET(DT_ALIAS(i2c_cells_b));

    for (int i = 0; i < CELLSIM_NUM_I2C_BUSES; i++) {
        if (!device_is_ready(i2c_bus[i])) {
            LOG_ERR("I2C bus %d not ready", i);
            return -ENODEV;
        }
        k_mutex_init(&i2c_lock[i]);
    }

    /* SPI bus init */
    spi_bus[0] = DEVICE_DT_GET(DT_ALIAS(spi_cells_a));
    spi_bus[1] = DEVICE_DT_GET(DT_ALIAS(spi_cells_b));

    for (int i = 0; i < 2; i++) {
        if (!device_is_ready(spi_bus[i])) {
            LOG_ERR("SPI bus %d not ready", i);
            return -ENODEV;
        }
        k_mutex_init(&spi_lock[i]);

        /* SPI config: mode 1 (CPOL=0, CPHA=1), 10 MHz, 8-bit, MSB first */
        spi_cfg[i].frequency = 10000000;
        spi_cfg[i].operation = SPI_WORD_SET(8) | SPI_TRANSFER_MSB |
                               SPI_MODE_CPHA;
        spi_cfg[i].cs = NULL;  /* CS managed by software GPIO */
    }

    /* ADC GPIO init (CS lines + MISO mux select) */
    ret = adc_gpio_init();
    if (ret != 0) {
        return ret;
    }

    /* Initialize each cell */
    for (uint8_t id = 0; id < CELL_COUNT; id++) {
        int bidx = i2c_idx(id);
        const struct device *bus = i2c_bus[bidx];

        /* I2C: configure GPIO expander + zero DACs */
        k_mutex_lock(&i2c_lock[bidx], K_FOREVER);

        ret = i2c_mux_select(id);
        if (ret != 0) {
            LOG_ERR("Cell %d: I2C mux select failed: %d", id, ret);
            k_mutex_unlock(&i2c_lock[bidx]);
            continue;
        }

        ret = tca6408_init_cell(bus);
        if (ret != 0) {
            LOG_WRN("Cell %d: GPIO init failed: %d", id, ret);
        }
        gpio_shadow[id] = 0x00;

        mcp4725_write(bus, MCP4725_BUCK_ADDR, 0);
        mcp4725_write(bus, MCP4725_LDO_ADDR, 0);

        i2c_mux_deselect(id);
        k_mutex_unlock(&i2c_lock[bidx]);

        /* SPI: initialize ADS131M04 (reset + configure) */
        int sidx = spi_idx(id);
        k_mutex_lock(&spi_lock[sidx], K_FOREVER);

        ret = ads131_init_cell(id);
        if (ret != 0) {
            LOG_WRN("Cell %d: ADC init failed: %d", id, ret);
        }

        k_mutex_unlock(&spi_lock[sidx]);

        memset(&cells[id], 0, sizeof(cells[id]));
    }

    LOG_INF("Cell HAL initialized (%d cells, I2C+SPI)", CELL_COUNT);
    return 0;
}

int cell_set_voltage(uint8_t cell_id, uint16_t mv)
{
    if (cell_id >= CELL_COUNT || mv > DAC_MAX_OUTPUT_MV) {
        return -EINVAL;
    }

    int bidx = i2c_idx(cell_id);
    const struct device *bus = i2c_bus[bidx];

    /* Buck tracks LDO output + headroom (spec §4.2.3) */
    uint16_t buck_mv = mv + LDO_HEADROOM_MV;
    if (buck_mv > BUCK_MAX_MV) {
        buck_mv = BUCK_MAX_MV;
    }

    uint16_t buck_code = mv_to_dac(buck_mv);
    uint16_t ldo_code = mv_to_dac(mv);

    k_mutex_lock(&i2c_lock[bidx], K_FOREVER);

    int ret = i2c_mux_select(cell_id);
    if (ret != 0) {
        k_mutex_unlock(&i2c_lock[bidx]);
        return ret;
    }

    ret = mcp4725_write(bus, MCP4725_BUCK_ADDR, buck_code);
    if (ret != 0) {
        LOG_ERR("Cell %d: buck DAC write failed: %d", cell_id, ret);
        i2c_mux_deselect(cell_id);
        k_mutex_unlock(&i2c_lock[bidx]);
        return ret;
    }

    ret = mcp4725_write(bus, MCP4725_LDO_ADDR, ldo_code);
    if (ret != 0) {
        LOG_ERR("Cell %d: LDO DAC write failed: %d", cell_id, ret);
    }

    i2c_mux_deselect(cell_id);
    k_mutex_unlock(&i2c_lock[bidx]);

    cells[cell_id].setpoint_mv = mv;
    return ret;
}

int cell_set_output(uint8_t cell_id, bool enable)
{
    if (cell_id >= CELL_COUNT) {
        return -EINVAL;
    }

    int bidx = i2c_idx(cell_id);
    const struct device *bus = i2c_bus[bidx];
    uint8_t gpio = gpio_shadow[cell_id];

    if (enable) {
        /* Power-on sequence: buck → LDO → relay */
        gpio |= GPIO_BUCK_EN | GPIO_LDO_EN;
    } else {
        /* Power-off: open relay + load switch first */
        gpio &= ~(GPIO_OUTPUT_RELAY | GPIO_LOAD_SWITCH | GPIO_EXT_LOAD_SW);
    }

    k_mutex_lock(&i2c_lock[bidx], K_FOREVER);

    int ret = i2c_mux_select(cell_id);
    if (ret != 0) {
        k_mutex_unlock(&i2c_lock[bidx]);
        return ret;
    }

    ret = tca6408_write_output(bus, gpio);
    if (ret != 0) {
        LOG_ERR("Cell %d: GPIO write failed: %d", cell_id, ret);
        i2c_mux_deselect(cell_id);
        k_mutex_unlock(&i2c_lock[bidx]);
        return ret;
    }
    gpio_shadow[cell_id] = gpio;

    if (enable) {
        /* Wait for regulators to stabilize, then close relay */
        k_sleep(K_MSEC(5));
        gpio |= GPIO_OUTPUT_RELAY;
        ret = tca6408_write_output(bus, gpio);
        gpio_shadow[cell_id] = gpio;
    } else {
        /* Disable regulators after relay opened */
        k_sleep(K_MSEC(2));
        gpio &= ~(GPIO_BUCK_EN | GPIO_LDO_EN);
        ret = tca6408_write_output(bus, gpio);
        gpio_shadow[cell_id] = gpio;
    }

    i2c_mux_deselect(cell_id);
    k_mutex_unlock(&i2c_lock[bidx]);

    cells[cell_id].output_enabled = enable;
    if (enable) {
        cells[cell_id].flags |= CELL_FLAG_OUTPUT_EN | CELL_FLAG_RELAY_CLOSED;
    } else {
        cells[cell_id].flags &= ~(CELL_FLAG_OUTPUT_EN | CELL_FLAG_RELAY_CLOSED);
    }

    return ret;
}

int cell_set_mode(uint8_t cell_id, bool four_wire)
{
    if (cell_id >= CELL_COUNT) {
        return -EINVAL;
    }

    int bidx = i2c_idx(cell_id);
    const struct device *bus = i2c_bus[bidx];
    uint8_t gpio = gpio_shadow[cell_id];

    if (four_wire) {
        gpio |= GPIO_FOUR_WIRE;
    } else {
        gpio &= ~GPIO_FOUR_WIRE;
    }

    k_mutex_lock(&i2c_lock[bidx], K_FOREVER);

    int ret = i2c_mux_select(cell_id);
    if (ret != 0) {
        k_mutex_unlock(&i2c_lock[bidx]);
        return ret;
    }

    ret = tca6408_write_output(bus, gpio);

    i2c_mux_deselect(cell_id);
    k_mutex_unlock(&i2c_lock[bidx]);

    if (ret == 0) {
        gpio_shadow[cell_id] = gpio;
        cells[cell_id].four_wire = four_wire;
        if (four_wire) {
            cells[cell_id].flags |= CELL_FLAG_FOUR_WIRE;
        } else {
            cells[cell_id].flags &= ~CELL_FLAG_FOUR_WIRE;
        }
    }

    return ret;
}

int cell_read_measurements(uint8_t cell_id, struct cell_state *state)
{
    if (cell_id >= CELL_COUNT || state == NULL) {
        return -EINVAL;
    }

    int ret;
    int32_t ch_data[4];

    /* SPI: read all 4 ADC channels (simultaneous conversion) */
    int sidx = spi_idx(cell_id);
    k_mutex_lock(&spi_lock[sidx], K_FOREVER);

    ret = ads131_read_channels(cell_id, ch_data);

    k_mutex_unlock(&spi_lock[sidx]);

    if (ret == 0) {
        state->buck_mv    = adc_raw_to_signal_mv(ch_data[ADC_CH_VBUCK], ADC_VDIV_VOLTAGE);
        state->ldo_mv     = adc_raw_to_signal_mv(ch_data[ADC_CH_VLDO],  ADC_VDIV_VOLTAGE);
        state->current_ua = adc_raw_to_current_ua(ch_data[ADC_CH_ISENSE]);
        state->voltage_mv = adc_raw_to_signal_mv(ch_data[ADC_CH_VSENSE], ADC_VDIV_VOLTAGE);

        /* Over-current check */
        if (state->current_ua > OVERCURRENT_UA) {
            state->flags |= CELL_FLAG_OVER_CURRENT;
        } else {
            state->flags &= ~CELL_FLAG_OVER_CURRENT;
        }
    }

    /* I2C: read temperature sensor */
    int bidx = i2c_idx(cell_id);
    k_mutex_lock(&i2c_lock[bidx], K_FOREVER);

    ret = i2c_mux_select(cell_id);
    if (ret == 0) {
        int16_t temp_c10;
        ret = tmp117_read(cell_i2c(cell_id), &temp_c10);
        if (ret == 0) {
            state->temp_c10 = temp_c10;
            if (temp_c10 > OVERTEMP_C10) {
                state->flags |= CELL_FLAG_OVER_TEMP;
            } else {
                state->flags &= ~CELL_FLAG_OVER_TEMP;
            }
        }
        i2c_mux_deselect(cell_id);
    }

    k_mutex_unlock(&i2c_lock[bidx]);

    /* Merge setpoint-side fields from cached state */
    state->setpoint_mv = cells[cell_id].setpoint_mv;
    state->output_enabled = cells[cell_id].output_enabled;
    state->four_wire = cells[cell_id].four_wire;
    state->flags = (state->flags & (CELL_FLAG_OVER_TEMP | CELL_FLAG_OVER_CURRENT)) |
                   (cells[cell_id].flags & ~(CELL_FLAG_OVER_TEMP | CELL_FLAG_OVER_CURRENT));
    state->selftest_passed = cells[cell_id].selftest_passed;

    /* Cache measurements */
    cells[cell_id].voltage_mv = state->voltage_mv;
    cells[cell_id].current_ua = state->current_ua;
    cells[cell_id].buck_mv = state->buck_mv;
    cells[cell_id].ldo_mv = state->ldo_mv;
    cells[cell_id].temp_c10 = state->temp_c10;

    return 0;
}

const struct cell_state *cell_get_state(uint8_t cell_id)
{
    if (cell_id >= CELL_COUNT) {
        return NULL;
    }
    return &cells[cell_id];
}

void cell_safe_state_all(void)
{
    LOG_WRN("Entering safe state: all cells OFF");

    for (uint8_t id = 0; id < CELL_COUNT; id++) {
        int bidx = i2c_idx(id);
        const struct device *bus = i2c_bus[bidx];

        k_mutex_lock(&i2c_lock[bidx], K_FOREVER);

        if (i2c_mux_select(id) == 0) {
            tca6408_write_output(bus, 0x00);
            gpio_shadow[id] = 0x00;

            mcp4725_write(bus, MCP4725_BUCK_ADDR, 0);
            mcp4725_write(bus, MCP4725_LDO_ADDR, 0);

            i2c_mux_deselect(id);
        }

        k_mutex_unlock(&i2c_lock[bidx]);

        cells[id].setpoint_mv = 0;
        cells[id].output_enabled = false;
        cells[id].flags &= ~(CELL_FLAG_OUTPUT_EN | CELL_FLAG_RELAY_CLOSED |
                              CELL_FLAG_LOAD_SW_ON);
    }
}
```

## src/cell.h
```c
/*
 * CellSim Card — Cell Control HAL
 *
 * Hardware abstraction for per-cell voltage/current control.
 *
 * Per-cell topology (isolated side):
 *   I2C path (behind TCA9548A mux + ISO1640 isolator):
 *     MCP4725 (0x61) — Buck converter DAC setpoint (A0=VIN)
 *     MCP4725 (0x60) — LDO fine-tune DAC setpoint (A0=GND)
 *     TCA6408 (0x20) — GPIO expander (relay, enable, cal, load, 4wire)
 *     TMP117  (0x49) — Temperature sensor (ADDR=VDD)
 *
 *   SPI path (behind ISO7741 isolator, per-cell CS):
 *     ADS131M04 — 24-bit 4-channel simultaneous ADC (Vbuck, Vldo, Isense, Vsense)
 *
 * Bus architecture:
 *   I2C1 → TCA9548A → Cells 0–3 (DACs + GPIO + temp)
 *   I2C2 → TCA9548A → Cells 4–7 (DACs + GPIO + temp)
 *   SPI1 → ISO7741 ×4 → Cells 0–3 ADC (MISO via CD74HC4052 mux)
 *   SPI2 → ISO7741 ×4 → Cells 4–7 ADC (MISO via CD74HC4052 mux)
 */

#ifndef CELLSIM_CELL_H
#define CELLSIM_CELL_H

#include <stdbool.h>
#include <stdint.h>

#define CELL_COUNT          8
#define CELLS_PER_BUS       4

/* ── TCA6408 GPIO bit assignments (spec §2.5) ─────────────────── */
#define GPIO_DMM_CAL        BIT(0)  /* DMM calibration relay */
/* bit 1 spare */
#define GPIO_BUCK_EN        BIT(2)  /* Buck converter enable */
#define GPIO_LDO_EN         BIT(3)  /* LDO enable */
#define GPIO_LOAD_SWITCH    BIT(4)  /* Internal load switch (discharge) */
#define GPIO_OUTPUT_RELAY   BIT(5)  /* Output DPDT relay */
#define GPIO_EXT_LOAD_SW    BIT(6)  /* External load switch */
#define GPIO_FOUR_WIRE      BIT(7)  /* 2-wire/4-wire mode select */

/* Convenience: all power-stage enables */
#define GPIO_ALL_ENABLES    (GPIO_BUCK_EN | GPIO_LDO_EN | GPIO_OUTPUT_RELAY | \
                             GPIO_LOAD_SWITCH | GPIO_EXT_LOAD_SW)

/* ── ADS131M04 channel assignments (spec §2.5, §4.2.8) ────────── */
#define ADC_CH_VBUCK        0   /* Buck output voltage (1:5 divider) */
#define ADC_CH_VLDO         1   /* LDO output voltage (1:5 divider) */
#define ADC_CH_ISENSE       2   /* Current sense amp output (2:5 divider) */
#define ADC_CH_VSENSE       3   /* Cell output voltage / Kelvin sense (1:5 divider) */

/* ── ADC scaling ───────────────────────────────────────────────── */
/*
 * ADS131M04: 24-bit delta-sigma, internal 1.2V reference, gain=1
 * Single-ended usable range: 0 to +1.2V
 * LSB = 1.2V / 2^23 = 143 nV
 *
 * Voltage dividers scale cell-domain signals into 0–1.2V:
 *   CH0/1/3 (voltage): 1:5 divider → 5V signal → 1.0V at ADC
 *   CH2 (current):     INA185 50× gain, 50mΩ shunt → 2:5 divider
 */
#define ADC_VREF_MV         1200    /* Internal reference 1.2V */
#define ADC_FULL_SCALE      8388608 /* 2^23 (24-bit, positive half) */

/* Voltage divider ratios (signal → ADC input) */
#define ADC_VDIV_VOLTAGE    5.0f    /* 1:5 for buck/LDO/sense channels */
#define ADC_VDIV_CURRENT    2.5f    /* 2:5 for current sense channel */

/* Current sensing */
#define ADC_IOUT_SHUNT_R    0.05f   /* 50 mΩ shunt resistor */
#define ADC_IOUT_INA_GAIN   50.0f   /* INA185A2 gain */

/* ── Protection thresholds ─────────────────────────────────────── */
#define OVERCURRENT_UA      1500000 /* 1.5 A — trip threshold */
#define OVERTEMP_C10        850     /* 85.0 °C */

/* ── Measurement flags (matches Python CellFlags in protocol.py) ─ */
#define CELL_FLAG_OUTPUT_EN     0x01
#define CELL_FLAG_RELAY_CLOSED  0x02
#define CELL_FLAG_LOAD_SW_ON    0x04
#define CELL_FLAG_FOUR_WIRE     0x08
#define CELL_FLAG_SELFTEST_PASS 0x10
#define CELL_FLAG_OVER_CURRENT  0x20
#define CELL_FLAG_OVER_TEMP     0x40

/* ── Per-cell runtime state ────────────────────────────────────── */
struct cell_state {
    /* Setpoints (written by CM5) */
    uint16_t setpoint_mv;       /* Target voltage in mV */
    bool     output_enabled;    /* Output relay + buck/LDO */
    bool     four_wire;         /* Kelvin mode */

    /* Measurements (read from SPI ADC) */
    uint16_t voltage_mv;        /* Measured output voltage (sense line) */
    uint32_t current_ua;        /* Measured output current */
    uint16_t buck_mv;           /* Buck converter output */
    uint16_t ldo_mv;            /* LDO output */
    int16_t  temp_c10;          /* Temperature × 10 (e.g., 251 = 25.1°C) */

    /* Status flags (CellFlags bitfield) */
    uint8_t  flags;

    /* Self-test result */
    bool     selftest_passed;
};

/**
 * Initialize cell control hardware.
 * Must be called after I2C and SPI buses are ready.
 *
 * @return 0 on success, negative errno on error
 */
int cell_init(void);

/**
 * Set the output voltage setpoint for a cell.
 * Writes to both buck DAC (tracking) and LDO DAC.
 *
 * @param cell_id  0–7
 * @param mv       Voltage in millivolts (0–5000)
 * @return 0 on success, negative errno on error
 */
int cell_set_voltage(uint8_t cell_id, uint16_t mv);

/**
 * Enable or disable cell output (relay + power stages).
 *
 * @param cell_id  0–7
 * @param enable   true = close relay + enable buck/LDO
 * @return 0 on success, negative errno on error
 */
int cell_set_output(uint8_t cell_id, bool enable);

/**
 * Set Kelvin sensing mode (2-wire or 4-wire).
 *
 * @param cell_id   0–7
 * @param four_wire true = 4-wire Kelvin mode
 * @return 0 on success, negative errno on error
 */
int cell_set_mode(uint8_t cell_id, bool four_wire);

/**
 * Read all measurements for a single cell.
 * Reads SPI ADC (4 channels) + I2C temp sensor.
 *
 * @param cell_id  0–7
 * @param state    Output: updated with latest measurements
 * @return 0 on success, negative errno on error
 */
int cell_read_measurements(uint8_t cell_id, struct cell_state *state);

/**
 * Get the current state of a cell (cached from last read).
 *
 * @param cell_id  0–7
 * @return Pointer to cell state, or NULL if invalid
 */
const struct cell_state *cell_get_state(uint8_t cell_id);

/**
 * Enter safe state: zero all DACs, open all relays for all cells.
 */
void cell_safe_state_all(void);

#endif /* CELLSIM_CELL_H */
```

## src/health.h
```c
/*
 * CellSim Card — Health Monitoring
 *
 * Reads STM32H7 internal sensors:
 *   - Die temperature (ADC3 internal channel 18)
 *   - Vrefint (ADC3 internal channel 19, for supply voltage estimation)
 *   - 24V input voltage via external resistor divider (ADC3 external channel)
 *
 * Health data is included in every UDP measurement packet.
 */

#ifndef CELLSIM_HEALTH_H
#define CELLSIM_HEALTH_H

#include <stdint.h>

/* Voltage divider ratio: 10k / (100k + 10k) = 1/11 */
#define VMON_DIVIDER_RATIO  11.0f

/* ADC reference voltage (V) */
#define ADC_VREF            3.3f

/* ADC resolution (12-bit) */
#define ADC_RESOLUTION      4096

/**
 * Initialize the health monitoring subsystem.
 * Configures ADC3 for internal temperature, Vrefint, and input voltage channels.
 *
 * @return 0 on success, negative errno on error
 */
int health_init(void);

/**
 * Read STM32H7 internal die temperature.
 *
 * @return Temperature in °C
 */
float health_get_mcu_temp(void);

/**
 * Read Vrefint (internal reference voltage).
 * Can be used to verify ADC calibration.
 *
 * @return Vrefint in V (nominally 1.21V)
 */
float health_get_vrefint(void);

/**
 * Read 24V input voltage via resistor divider.
 * Divider: 100k/10k = 1:11 ratio.
 *
 * @return Input voltage in V
 */
float health_get_input_voltage(void);

/**
 * Health data structure for inclusion in measurement packets.
 */
struct health_data {
    float mcu_temp_celsius;
    float vrefint_volts;
    float input_voltage;
    uint32_t uptime_ms;
};

/**
 * Get all health data in one call.
 */
void health_get_all(struct health_data *data);

#endif /* CELLSIM_HEALTH_H */
```

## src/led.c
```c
/*
 * CellSim Card — Status LED (SK6805-EC20, WS2812-compatible)
 *
 * Uses Zephyr's led_strip API with the ws2812-gpio driver.
 * Single LED on PF13, configured via device tree overlay.
 */

#include "led.h"

#include <zephyr/kernel.h>
#include <zephyr/device.h>
#include <zephyr/drivers/led_strip.h>
#include <zephyr/logging/log.h>

LOG_MODULE_REGISTER(led, LOG_LEVEL_INF);

#define STRIP_NODE DT_ALIAS(led_strip)

#if !DT_NODE_HAS_STATUS_OKAY(STRIP_NODE)
#warning "Status LED (led-strip alias) not found in device tree — LED functions will be no-ops"
#endif

static const struct device *strip_dev = DEVICE_DT_GET_OR_NULL(STRIP_NODE);
static struct led_rgb pixel;
static bool led_ready;

int led_init(void)
{
    if (strip_dev == NULL) {
        LOG_WRN("Status LED device not found in device tree");
        return -ENODEV;
    }

    if (!device_is_ready(strip_dev)) {
        LOG_WRN("Status LED device not ready");
        return -ENODEV;
    }

    led_ready = true;
    LOG_INF("Status LED initialized");

    /* Start with LED off */
    led_off();
    return 0;
}

void led_set_color(uint8_t r, uint8_t g, uint8_t b)
{
    if (!led_ready) {
        return;
    }

    pixel.r = r;
    pixel.g = g;
    pixel.b = b;

    int ret = led_strip_update_rgb(strip_dev, &pixel, 1);
    if (ret != 0) {
        LOG_ERR("LED strip update failed: %d", ret);
    }
}

void led_set_status_booting(void)
{
    led_set_color(0x00, 0x00, 0xFF); /* Blue */
}

void led_set_status_ok(void)
{
    led_set_color(0x00, 0xFF, 0x00); /* Green */
}

void led_set_status_warning(void)
{
    led_set_color(0xFF, 0x80, 0x00); /* Yellow/amber */
}

void led_set_status_fault(void)
{
    led_set_color(0xFF, 0x00, 0x00); /* Red */
}

void led_set_status_updating(void)
{
    led_set_color(0xFF, 0xFF, 0xFF); /* White */
}

void led_off(void)
{
    led_set_color(0x00, 0x00, 0x00); /* Off */
}
```
